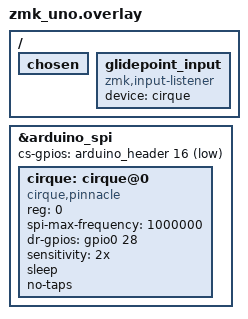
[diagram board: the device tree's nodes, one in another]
/ {
	chosen {
		/delete-node/ zmk,underglow;
	};

    glidepoint_input {
        compatible = "zmk,input-listener";
        device = <&cirque>;
    };
};

&arduino_spi {
	/delete-node/ led_strip;
	/delete-node/ ls0xx@0;

	status = "okay";
	cs-gpios = <&arduino_header 16 GPIO_ACTIVE_LOW>;

	cirque: cirque@0 {
		compatible = "cirque,pinnacle";
		reg = <0>;
		status = "okay";
		spi-max-frequency = <1000000>;

		dr-gpios = <&gpio0 28 (GPIO_ACTIVE_HIGH)>;
		sensitivity = "2x";
		sleep;
		no-taps;
	};
};

